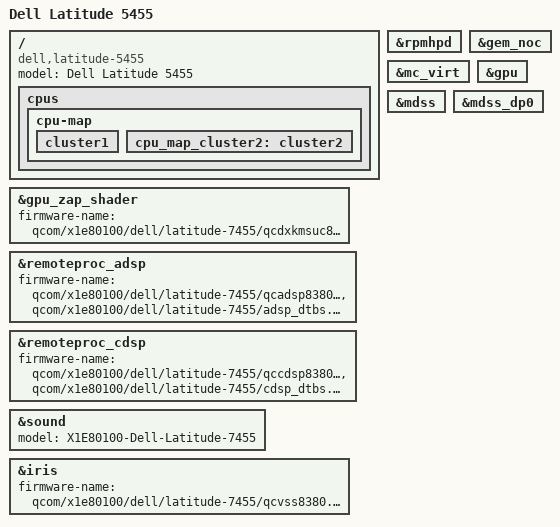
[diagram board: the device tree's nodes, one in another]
/dts-v1/;

#include "hamoa.dtsi"
#include "x1-dell-thena.dtsi"

/ {
        model = "Dell Latitude 5455";
        compatible = "dell,latitude-5455", "qcom,x1e80100";

        cpus {
        /delete-node/ cpu@10300; /* CPU7 */
        /delete-node/ cpu@20300; /* CPU11 */

        cpu-map {
            cluster1 {
                /delete-node/ core3; /* This is CPU7 on your 10-core chip */
            };
            cpu_map_cluster2: cluster2 {
                /delete-node/ core3; /* This is CPU11 on your 10-core chip */
            };
        };
        };
};

/* Power & Interconnects */
&rpmhpd {
    status = "okay";
};

&gem_noc {
    status = "okay";
};

&mc_virt {
    status = "okay";
};

/* GPU */
&gpu {
    status = "okay";
};

&gpu_zap_shader {
    firmware-name = "qcom/x1e80100/dell/latitude-7455/qcdxkmsuc8380.mbn";
};

/* Display */
&mdss {
    status = "okay";
};

&mdss_dp0 {
    status = "okay";
};

/* Audio DSPs */
&remoteproc_adsp {
    firmware-name = "qcom/x1e80100/dell/latitude-7455/qcadsp8380.mbn",
                    "qcom/x1e80100/dell/latitude-7455/adsp_dtbs.elf";
    status = "okay";
};

&remoteproc_cdsp {
    firmware-name = "qcom/x1e80100/dell/latitude-7455/qccdsp8380.mbn",
                    "qcom/x1e80100/dell/latitude-7455/cdsp_dtbs.elf";
    status = "okay";
};

/* Audio  */
&sound {
    model = "X1E80100-Dell-Latitude-7455";
};

/* Video Encoder/Decoder (Hardware Video Acceleration) */
&iris {
    firmware-name = "qcom/x1e80100/dell/latitude-7455/qcvss8380.mbn";
    status = "okay";
};
